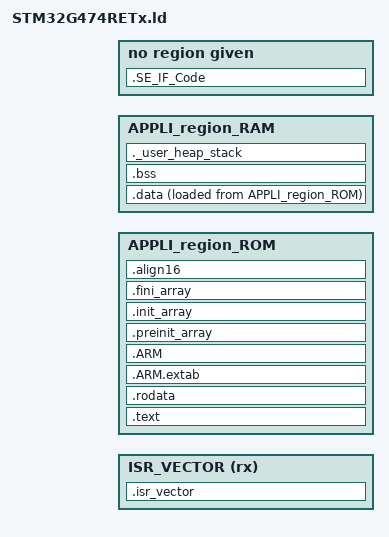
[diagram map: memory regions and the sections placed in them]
/*
*****************************************************************************
**
**  File        : LinkerScript.ld
**
**  Abstract    : Linker script for STM32G474RETx Device with
**                512KByte FLASH, 128KByte RAM
**
**                Set heap size, stack size and stack location according
**                to application requirements.
**
**                Set memory bank area and size if external memory is used.
**
**  Target      : STMicroelectronics STM32
**
**
**  Distribution: The file is distributed as is, without any warranty
**                of any kind.
**
**  (c)Copyright Ac6.
**  You may use this file as-is or modify it according to the needs of your
**  project. Distribution of this file (unmodified or modified) is not
**  permitted. Ac6 permit registered System Workbench for MCU users the
**  rights to distribute the assembled, compiled & linked contents of this
**  file as part of an application binary file, provided that it is built
**  using the System Workbench for MCU toolchain.
**
*****************************************************************************
*/

/* Entry Point */
ENTRY(Reset_Handler)

/* Highest address of the user mode stack */
_estack = 0x20018000;    /* end of SB_SRAM1*/
/* Generate a link error if heap and stack don't fit into RAM */
_Min_Heap_Size = 0x200;      /* required amount of heap  */
_Min_Stack_Size = 0x800; /* required amount of stack */

INCLUDE mapping_fwimg.ld
INCLUDE mapping_sbsfu.ld

/* Specify the memory areas */
__ICFEDIT_intvec_start__  = __ICFEDIT_SLOT_Active_1_start__    + 0x1000;
APPLI_region_ROM_start    = __ICFEDIT_SLOT_Active_1_start__    + VECTOR_SIZE + 0x1000;
APPLI_region_ROM_length   = __ICFEDIT_SLOT_Active_1_end__    - APPLI_region_ROM_start + 1;
APPLI_region_RAM_start    = __ICFEDIT_SE_region_RAM_end__ + 1;
APPLI_region_RAM_length    = 0x2001B000 - APPLI_region_RAM_start;
MEMORY
{
 ISR_VECTOR (rx)   : ORIGIN = __ICFEDIT_intvec_start__, LENGTH = VECTOR_SIZE
 APPLI_region_ROM  : ORIGIN = APPLI_region_ROM_start, LENGTH = APPLI_region_ROM_length
 APPLI_region_RAM  : ORIGIN = APPLI_region_RAM_start, LENGTH = APPLI_region_RAM_length
}

/* Define output sections */
SECTIONS
{
  /* The startup code goes first into FLASH */
  .isr_vector :
  {
    . = ALIGN(8);
    KEEP(*(.isr_vector)) /* Startup code */
    FILL(0);
    . = ORIGIN(ISR_VECTOR) + LENGTH(ISR_VECTOR) - 1;
    BYTE(0)
    . = ALIGN(8);
  } >ISR_VECTOR

  .SE_IF_Code : {
  KEEP(*se_interface_app.o (.text .text*))
  } >SE_IF_region_ROM

  /* The program code and other data goes into FLASH */
  .text :
  {
    . = ALIGN(8);
    *(.text)           /* .text sections (code) */
    *(.text*)          /* .text* sections (code) */
    *(.glue_7)         /* glue arm to thumb code */
    *(.glue_7t)        /* glue thumb to arm code */
    *(.eh_frame)

    KEEP (*(.init))
    KEEP (*(.fini))

    . = ALIGN(8);
    _etext = .;        /* define a global symbols at end of code */
  } >APPLI_region_ROM

  /* Constant data goes into FLASH */
  .rodata :
  {
    . = ALIGN(8);
    *(.rodata)         /* .rodata sections (constants, strings, etc.) */
    *(.rodata*)        /* .rodata* sections (constants, strings, etc.) */
    . = ALIGN(8);
  } >APPLI_region_ROM

  .ARM.extab   :
  {
  . = ALIGN(8);
  *(.ARM.extab* .gnu.linkonce.armextab.*)
  . = ALIGN(8);
  } >APPLI_region_ROM
  .ARM : {
	. = ALIGN(8);
    __exidx_start = .;
    *(.ARM.exidx*)
    __exidx_end = .;
	. = ALIGN(8);
  } >APPLI_region_ROM

  .preinit_array     :
  {
	. = ALIGN(8);
    PROVIDE_HIDDEN (__preinit_array_start = .);
    KEEP (*(.preinit_array*))
    PROVIDE_HIDDEN (__preinit_array_end = .);
	. = ALIGN(8);
  } >APPLI_region_ROM

  .init_array :
  {
	. = ALIGN(8);
    PROVIDE_HIDDEN (__init_array_start = .);
    KEEP (*(SORT(.init_array.*)))
    KEEP (*(.init_array*))
    PROVIDE_HIDDEN (__init_array_end = .);
	. = ALIGN(8);
  } >APPLI_region_ROM
  .fini_array :
  {
	. = ALIGN(8);
    PROVIDE_HIDDEN (__fini_array_start = .);
    KEEP (*(SORT(.fini_array.*)))
    KEEP (*(.fini_array*))
    PROVIDE_HIDDEN (__fini_array_end = .);
	. = ALIGN(8);
  } >APPLI_region_ROM

  /* used by the startup to initialize data */
  _sidata = LOADADDR(.data);

  /* Initialized data sections goes into RAM, load LMA copy after code */
  .data :
  {
    . = ALIGN(8);
    _sdata = .;        /* create a global symbol at data start */
    *(.data)           /* .data sections */
    *(.data*)          /* .data* sections */

    . = ALIGN(8);
    _edata = .;        /* define a global symbol at data end */
  } >APPLI_region_RAM AT>APPLI_region_ROM

  /* Extra ROM section (last one) to make sure the binary size is a multiple of the AES block size (16 bytes) and G4 flash writing unit (8 bytes)*/
  .align16 :
  {
    . = . + 1;         /* _edata=. is aligned on 8 bytes so could be aligned on 16 bytes: add 1 byte gap */
    . = ALIGN(16) - 1; /* increment the location counter until next 16 bytes aligned address (-1 byte)   */
    BYTE(0);           /* allocate 1 byte (value is 0) to be a multiple of 16 bytes                      */
  } > APPLI_region_ROM

  /* Uninitialized data section */
  . = ALIGN(4);
  .bss :
  {
    /* This is used by the startup in order to initialize the .bss section */
    _sbss = .;         /* define a global symbol at bss start */
    __bss_start__ = _sbss;
    *(.bss)
    *(.bss*)
    *(COMMON)

    . = ALIGN(4);
    _ebss = .;         /* define a global symbol at bss end */
    __bss_end__ = _ebss;
  } >APPLI_region_RAM

  /* User_heap_stack section, used to check that there is enough RAM left */
  ._user_heap_stack :
  {
    . = ALIGN(8);
    PROVIDE ( end = . );
    PROVIDE ( _end = . );
    . = . + _Min_Heap_Size;
    . = . + _Min_Stack_Size;
    . = ALIGN(8);
  } >APPLI_region_RAM



  /* Remove information from the standard libraries */
  /DISCARD/ :
  {
    libc.a ( * )
    libm.a ( * )
    libgcc.a ( * )
  }

  .ARM.attributes 0 : { *(.ARM.attributes) }
}


